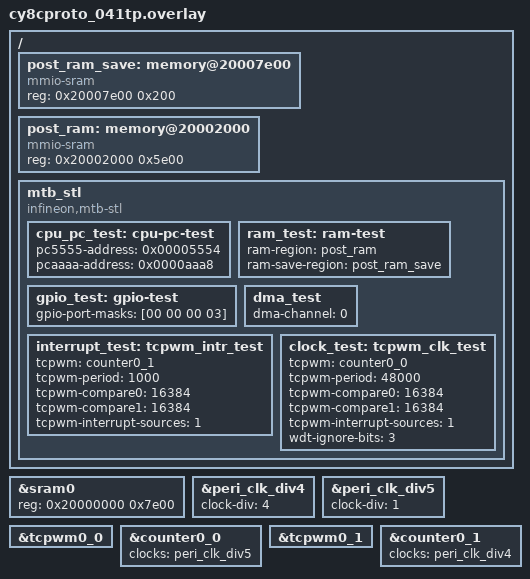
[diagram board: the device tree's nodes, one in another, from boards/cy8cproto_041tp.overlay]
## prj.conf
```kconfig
# POST subsystem
CONFIG_POST=y
CONFIG_POST_VENDOR_MTB_STL=y
CONFIG_POST_SHELL=y
CONFIG_POST_HALT_ON_FAILURE=n
CONFIG_POST_RUNTIME_TESTS=y

# Shell support
CONFIG_SHELL=y

# Logging
CONFIG_LOG=y
CONFIG_POST_LOG_LEVEL=4

# Shared interrupts
# Note: This config is enabled by default.
# This config enables to have multiple ISR for same irq line,
# since both test and drivers use same irq line
CONFIG_SHARED_INTERRUPTS=y
```

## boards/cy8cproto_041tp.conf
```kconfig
# SPDX-FileCopyrightText: Copyright (c) 2026 Infineon Technologies AG,
# SPDX-FileCopyrightText: or an affiliate of Infineon Technologies AG. All rights reserved.
#
# SPDX-License-Identifier: Apache-2.0

# Enable MTB-STL tests
CONFIG_POST_MTB_STL_STARTUP_CFGREG=y
CONFIG_POST_MTB_STL_SAVE_STARTUP_CFGREG=y
CONFIG_POST_MTB_STL_CPU_REGS=y
CONFIG_POST_MTB_STL_CPU_PC=y
CONFIG_POST_MTB_STL_PROGRAM_FLOW=y
CONFIG_POST_MTB_STL_RAM_MARCH=y
CONFIG_POST_MTB_STL_STACK=y
CONFIG_POST_MTB_STL_FLASH=y
CONFIG_POST_MTB_STL_GPIO=y
CONFIG_POST_MTB_STL_WDT=y
CONFIG_POST_MTB_STL_DMA=y
CONFIG_POST_MTB_STL_INTERRUPT=y
CONFIG_POST_MTB_STL_CLOCK=y

# Zephyr driver configs
CONFIG_COUNTER=y
```

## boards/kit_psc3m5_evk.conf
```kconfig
# SPDX-FileCopyrightText: Copyright (c) 2026 Infineon Technologies AG,
# SPDX-FileCopyrightText: or an affiliate of Infineon Technologies AG. All rights reserved.
#
# SPDX-License-Identifier: Apache-2.0

# Enable MTB-STL tests
CONFIG_POST_MTB_STL_STARTUP_CFGREG=y
CONFIG_POST_MTB_STL_SAVE_STARTUP_CFGREG=y
CONFIG_POST_MTB_STL_CPU_REGS=y
CONFIG_POST_MTB_STL_CPU_PC=y
CONFIG_POST_MTB_STL_PROGRAM_FLOW=y
CONFIG_POST_MTB_STL_RAM_MARCH=y
CONFIG_POST_MTB_STL_STACK=y
CONFIG_POST_MTB_STL_FLASH=y
CONFIG_POST_MTB_STL_GPIO=y
CONFIG_POST_MTB_STL_WDT=y
CONFIG_POST_MTB_STL_INTERRUPT=y
CONFIG_POST_MTB_STL_CLOCK=y
CONFIG_POST_MTB_STL_FPU=y
CONFIG_POST_MTB_STL_DMA=y

# Zephyr driver configs
CONFIG_COUNTER=y
CONFIG_FPU=y
CONFIG_DYNAMIC_INTERRUPTS=y
```

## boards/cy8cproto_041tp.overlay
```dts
/*
 * SPDX-FileCopyrightText: Copyright (c) 2026 Infineon Technologies AG,
 * SPDX-FileCopyrightText: or an affiliate of Infineon Technologies AG. All rights reserved.
 *
 * SPDX-License-Identifier: Apache-2.0
 */

/*
 * MTB-STL POST overlay for CY8CPROTO-041TP
 */

&sram0 {
	reg = <0x20000000 0x7e00>;
};

/*
 * Clock dividers for TCPWM test peripherals
 */

&peri_clk_div4 {
	status = "okay";
	clock-div = <4>;
	/* Interrupt test: divider 4 -> TCPWM counter 1 */
};

&peri_clk_div5 {
	status = "okay";
	clock-div = <1>;
	/* Clock test: divider 5 -> TCPWM counter 0, full 48 MHz */
};

/*
 * Enable TCPWM instances and assign clock dividers
 */

&tcpwm0_0 {
	status = "okay";
};

&counter0_0 {
	status = "okay";
	clocks = <&peri_clk_div5>;
};

&tcpwm0_1 {
	status = "okay";
};

&counter0_1 {
	status = "okay";
	clocks = <&peri_clk_div4>;
};

/ {
	post_ram_save: memory@20007e00 {
		compatible = "mmio-sram";
		reg = <0x20007e00 0x200>;
	};

	post_ram: memory@20002000 {
		compatible = "mmio-sram";
		reg = <0x20002000 0x5e00>;
	};

	mtb_stl: mtb_stl {
		compatible = "infineon,mtb-stl";
		status = "okay";

		cpu_pc_test: cpu-pc-test {
			pc5555-address = <0x00005554>;
			pcaaaa-address = <0x0000aaa8>;
		};

		ram_test: ram-test {
			ram-region = <&post_ram>;
			ram-save-region = <&post_ram_save>;
		};

		gpio_test: gpio-test {
			gpio-port-masks = [00 00 00 03];
		};

		/* DMA test */
		dma_test: dma_test {
			dma-channel = <0>;
		};

		/*
		 * Interrupt test: TCPWM counter 1 generates periodic interrupts.
		 * Verifies ISR fires at expected frequency.
		 *
		 * Clock: counter0_1 -> peri_clk_div4 (assigned above)
		 * IRQ: inherited from parent tcpwm0_1 (IRQ 17)
		 */
		interrupt_test: tcpwm_intr_test {
			tcpwm = <&counter0_1>;
			tcpwm-period = <1000>;
			tcpwm-compare0 = <16384>;
			tcpwm-compare1 = <16384>;
			tcpwm-interrupt-sources = <1>;
		};

		/*
		 * Clock accuracy test: TCPWM counter 0 at full 48 MHz,
		 * cross-checked against ILO/WDT.
		 *
		 * Clock: counter0_0 -> peri_clk_div5 (assigned on counter node above)
		 * IRQ: inherited from parent tcpwm0_0 (IRQ 16)
		 *
		 * wdt-ignore-bits: Controls WDT match period for cross-check.
		 *   Higher values -> coarser WDT period -> wider tolerance.
		 *   3 = ignore lower 3 bits of WDT counter.
		 */
		clock_test: tcpwm_clk_test {
			tcpwm = <&counter0_0>;
			tcpwm-period = <48000>;
			tcpwm-compare0 = <16384>;
			tcpwm-compare1 = <16384>;
			tcpwm-interrupt-sources = <1>;
			wdt-ignore-bits = <3>;
		};
	};
};
```

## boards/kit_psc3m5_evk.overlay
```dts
/*
 * SPDX-FileCopyrightText: Copyright (c) 2026 Infineon Technologies AG,
 * SPDX-FileCopyrightText: or an affiliate of Infineon Technologies AG. All rights reserved.
 *
 * SPDX-License-Identifier: Apache-2.0
 */

#include <zephyr/dt-bindings/gpio/gpio.h>

&sram0 {
	reg = <0x34000000 0xfe00>;
};

&peri0_group5_16bit_2 {
	status = "okay";
	clock-div = <1>;
};

&tcpwm0_1 {
	status = "okay";
};

&counter0_1 {
	status = "okay";
	clocks = <&peri0_group5_16bit_2>;
};

&peri0_group5_8bit_0 {
	status = "okay";
	clock-div = <1>;
};

&tcpwm0_0 {
	status = "okay";
};

&counter0_0 {
	status = "okay";
	clocks = <&peri0_group5_8bit_0>;
};

/ {
	post_ram_save: memory@3400fe00 {
		compatible = "mmio-sram";
		reg = <0x3400fe00 0x200>;
	};

	post_ram: memory@34002000 {
		compatible = "mmio-sram";
		reg = <0x34002000 0xde00>;
	};

	mtb_stl: mtb_stl {
		compatible = "infineon,mtb-stl";
		status = "okay";

		cpu_pc_test: cpu-pc-test {
			pc5555-address = <0x12015554>;
			pcaaaa-address = <0x1201aaa8>;
		};

		ram_test: ram-test {
			ram-region = <&post_ram>;
			ram-save-region = <&post_ram_save>;
		};

		gpio_test: gpio-test {
			gpio-port-masks = [00 00 00 03];
		};

		interrupt_test: tcpwm_intr_test {
			tcpwm = <&counter0_1>;
			tcpwm-period = <9600>;
			tcpwm-compare0 = <16384>;
			tcpwm-compare1 = <16384>;
			tcpwm-interrupt-sources = <1>;
		};

		clock_test: tcpwm_clk_test {
			tcpwm = <&counter0_0>;
			tcpwm-period = <35000>;
			tcpwm-compare0 = <35000>;
			tcpwm-compare1 = <16384>;
			tcpwm-interrupt-sources = <1>;
			wdt-ignore-bits = <0>;
		};

		dma_test: dma_test {
			dma-channel = <0>;
			dma-preemptable;
		};
	};
};
```

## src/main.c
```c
/*
 * Copyright (c) 2026 Aerlync Labs Inc.
 * SPDX-License-Identifier: Apache-2.0
 */

#include <zephyr/kernel.h>
#include <zephyr/post/post.h>
#include <zephyr/shell/shell.h>
#include <zephyr/logging/log.h>

#if defined(CONFIG_SHELL) && defined(CONFIG_POST_MTB_STL_SAVE_STARTUP_CFGREG)
#include <errno.h>
#include <mtb_stl/startup.h>
#endif

LOG_MODULE_REGISTER(post_sample, LOG_LEVEL_INF);

#if defined(CONFIG_SHELL) && defined(CONFIG_POST_MTB_STL_SAVE_STARTUP_CFGREG)
static int cmd_startup_save(const struct shell *sh, size_t argc, char **argv)
{
	ARG_UNUSED(argc);
	ARG_UNUSED(argv);

	int ret = mtb_stl_startup_provision();

	if (ret == 0) {
		shell_print(sh, "Startup reference save: PASS");
	} else if (ret == -EALREADY) {
		shell_error(sh, "Startup reference save: NOT SAVED "
			    "(reference is not blank; no write performed)");
	} else {
		shell_error(sh, "Startup reference save: FAIL (%d)", ret);
	}

	return ret;
}

SHELL_STATIC_SUBCMD_SET_CREATE(
	startup_cmds,
	SHELL_CMD_ARG(save, NULL, "Save the current known-good startup reference to blank flash",
		      cmd_startup_save, 1, 0),
	SHELL_SUBCMD_SET_END);

SHELL_CMD_REGISTER(stl_startup, &startup_cmds, "Explicit startup reference provisioning", NULL);
#endif

static struct {
	uint32_t passed;
	uint32_t failed;
	uint32_t skipped;
} summary;

int main(void)
{
	printk("\n");
	printk("====================================\n");
	printk("Starting POST sample application\n");
	printk("====================================\n");
	printk("\n");

	LOG_INF("POST subsystem initialized");
	LOG_INF("MTB-STL tests registered during boot");

	post_get_summary(&summary.passed, &summary.failed, &summary.skipped);
	printk("POST summary: %u passed, %u failed, %u skipped\n",
	       summary.passed, summary.failed, summary.skipped);

	printk("Available shell commands:\n");
	printk("  post list   - List all registered POST tests\n");
	printk("  post run <id> | --all - Run runtime POST tests\n");
	printk("  post status - Show POST test results\n");
#if defined(CONFIG_SHELL) && defined(CONFIG_POST_MTB_STL_SAVE_STARTUP_CFGREG)
	printk("  stl_startup save - Explicitly save a startup reference to blank flash\n");
#endif
	printk("\n");

	/* Application main loop */
	while (1) {
		k_sleep(K_SECONDS(5));
		LOG_DBG("Application running...");
	}

	return 0;
}
```
